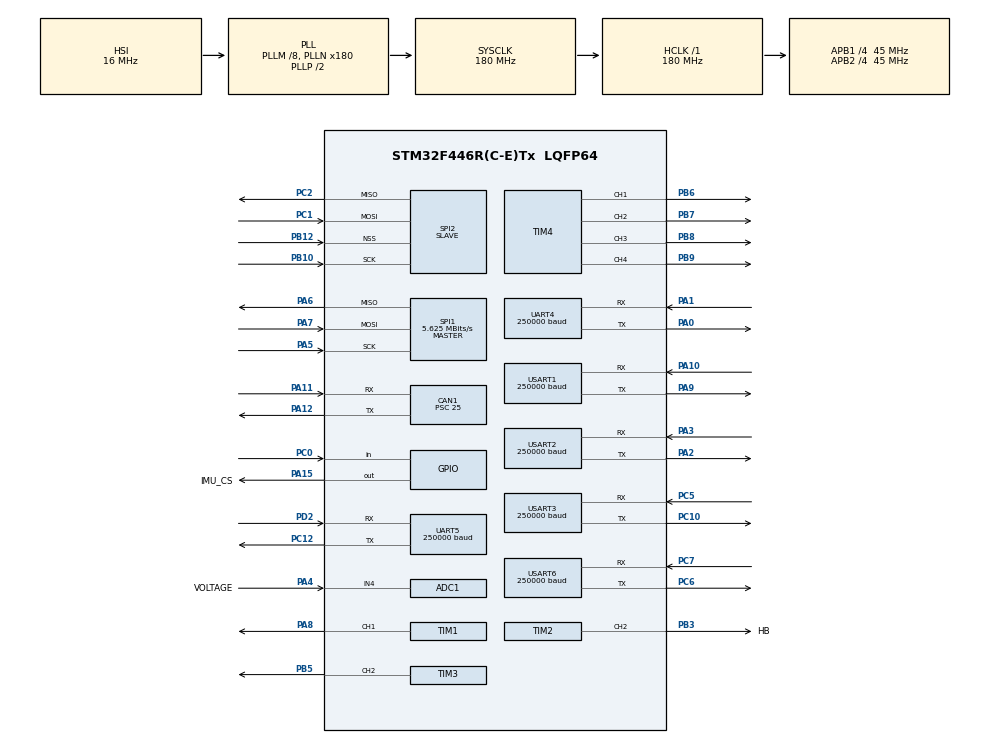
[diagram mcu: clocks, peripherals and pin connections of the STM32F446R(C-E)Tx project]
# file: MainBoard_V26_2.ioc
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ADC1.Channel-0\#ChannelRegularConversion=ADC_CHANNEL_4
ADC1.ContinuousConvMode=ENABLE
ADC1.DMAContinuousRequests=ENABLE
ADC1.NbrOfConversionFlag=1
ADC1.Rank-0\#ChannelRegularConversion=1
ADC1.SamplingTime-0\#ChannelRegularConversion=ADC_SAMPLETIME_56CYCLES
ADC1.ScanConvMode=ENABLE
ADC1.master=1
CAN1.BS1=CAN_BS1_15TQ
CAN1.BS2=CAN_BS2_2TQ
CAN1.CalculateBaudRate=100000
CAN1.CalculateTimeBit=10000
CAN1.CalculateTimeQuantum=555.5555555555555
CAN1.Prescaler=25
CAN1.TTCM=ENABLE
CAN1.TXFP=ENABLE
Dma.ADC1.10.Direction=DMA_PERIPH_TO_MEMORY
Dma.ADC1.10.FIFOMode=DMA_FIFOMODE_DISABLE
Dma.ADC1.10.Instance=DMA2_Stream0
Dma.ADC1.10.MemDataAlignment=DMA_MDATAALIGN_HALFWORD
Dma.ADC1.10.MemInc=DMA_MINC_ENABLE
Dma.ADC1.10.Mode=DMA_CIRCULAR
Dma.ADC1.10.PeriphDataAlignment=DMA_PDATAALIGN_HALFWORD
Dma.ADC1.10.PeriphInc=DMA_PINC_DISABLE
Dma.ADC1.10.Priority=DMA_PRIORITY_LOW
Dma.Request0=UART4_RX
Dma.Request1=SPI2_TX
Dma.Request10=ADC1
Dma.Request2=USART2_RX
Dma.Request3=USART2_TX
Dma.Request4=USART3_RX
Dma.Request5=SPI2_RX
Dma.Request6=UART5_RX
Dma.Request7=UART5_TX
Dma.Request8=USART6_RX
Dma.Request9=USART6_TX
Dma.SPI2_TX.1.Direction=DMA_MEMORY_TO_PERIPH
Dma.SPI2_TX.1.FIFOMode=DMA_FIFOMODE_DISABLE
Dma.SPI2_TX.1.Instance=DMA1_Stream4
Dma.SPI2_TX.1.MemDataAlignment=DMA_MDATAALIGN_BYTE
Dma.SPI2_TX.1.MemInc=DMA_MINC_ENABLE
Dma.SPI2_TX.1.Mode=DMA_NORMAL
Dma.SPI2_TX.1.PeriphDataAlignment=DMA_PDATAALIGN_BYTE
Dma.SPI2_TX.1.PeriphInc=DMA_PINC_DISABLE
Dma.SPI2_TX.1.Priority=DMA_PRIORITY_VERY_HIGH
Dma.SPI2_RX.5.Direction=DMA_PERIPH_TO_MEMORY
Dma.SPI2_RX.5.FIFOMode=DMA_FIFOMODE_DISABLE
Dma.SPI2_RX.5.Instance=DMA1_Stream3
Dma.SPI2_RX.5.MemDataAlignment=DMA_MDATAALIGN_BYTE
Dma.SPI2_RX.5.MemInc=DMA_MINC_ENABLE
Dma.SPI2_RX.5.Mode=DMA_NORMAL
Dma.SPI2_RX.5.PeriphDataAlignment=DMA_PDATAALIGN_BYTE
Dma.SPI2_RX.5.PeriphInc=DMA_PINC_DISABLE
Dma.SPI2_RX.5.Priority=DMA_PRIORITY_VERY_HIGH
Dma.UART4_RX.0.Direction=DMA_PERIPH_TO_MEMORY
Dma.UART4_RX.0.FIFOMode=DMA_FIFOMODE_DISABLE
Dma.UART4_RX.0.Instance=DMA1_Stream2
Dma.UART4_RX.0.MemDataAlignment=DMA_MDATAALIGN_BYTE
Dma.UART4_RX.0.MemInc=DMA_MINC_ENABLE
Dma.UART4_RX.0.Mode=DMA_CIRCULAR
Dma.UART4_RX.0.PeriphDataAlignment=DMA_PDATAALIGN_BYTE
Dma.UART4_RX.0.PeriphInc=DMA_PINC_DISABLE
Dma.UART4_RX.0.Priority=DMA_PRIORITY_LOW
Dma.UART5_RX.6.Direction=DMA_PERIPH_TO_MEMORY
Dma.UART5_RX.6.FIFOMode=DMA_FIFOMODE_DISABLE
Dma.UART5_RX.6.Instance=DMA1_Stream0
Dma.UART5_RX.6.MemDataAlignment=DMA_MDATAALIGN_BYTE
Dma.UART5_RX.6.MemInc=DMA_MINC_ENABLE
Dma.UART5_RX.6.Mode=DMA_CIRCULAR
Dma.UART5_RX.6.PeriphDataAlignment=DMA_PDATAALIGN_BYTE
Dma.UART5_RX.6.PeriphInc=DMA_PINC_DISABLE
Dma.UART5_RX.6.Priority=DMA_PRIORITY_LOW
Dma.UART5_TX.7.Direction=DMA_MEMORY_TO_PERIPH
Dma.UART5_TX.7.FIFOMode=DMA_FIFOMODE_DISABLE
Dma.UART5_TX.7.Instance=DMA1_Stream7
Dma.UART5_TX.7.MemDataAlignment=DMA_MDATAALIGN_BYTE
Dma.UART5_TX.7.MemInc=DMA_MINC_ENABLE
Dma.UART5_TX.7.Mode=DMA_NORMAL
Dma.UART5_TX.7.PeriphDataAlignment=DMA_PDATAALIGN_BYTE
Dma.UART5_TX.7.PeriphInc=DMA_PINC_DISABLE
Dma.UART5_TX.7.Priority=DMA_PRIORITY_LOW
Dma.USART2_RX.2.Direction=DMA_PERIPH_TO_MEMORY
Dma.USART2_RX.2.FIFOMode=DMA_FIFOMODE_DISABLE
Dma.USART2_RX.2.Instance=DMA1_Stream5
Dma.USART2_RX.2.MemDataAlignment=DMA_MDATAALIGN_BYTE
Dma.USART2_RX.2.MemInc=DMA_MINC_ENABLE
Dma.USART2_RX.2.Mode=DMA_CIRCULAR
Dma.USART2_RX.2.PeriphDataAlignment=DMA_PDATAALIGN_BYTE
Dma.USART2_RX.2.PeriphInc=DMA_PINC_DISABLE
Dma.USART2_RX.2.Priority=DMA_PRIORITY_LOW
Dma.USART2_TX.3.Direction=DMA_MEMORY_TO_PERIPH
Dma.USART2_TX.3.FIFOMode=DMA_FIFOMODE_DISABLE
Dma.USART2_TX.3.Instance=DMA1_Stream6
Dma.USART2_TX.3.MemDataAlignment=DMA_MDATAALIGN_BYTE
Dma.USART2_TX.3.MemInc=DMA_MINC_ENABLE
Dma.USART2_TX.3.Mode=DMA_NORMAL
Dma.USART2_TX.3.PeriphDataAlignment=DMA_PDATAALIGN_BYTE
Dma.USART2_TX.3.PeriphInc=DMA_PINC_DISABLE
Dma.USART2_TX.3.Priority=DMA_PRIORITY_LOW
Dma.USART3_RX.4.Direction=DMA_PERIPH_TO_MEMORY
Dma.USART3_RX.4.FIFOMode=DMA_FIFOMODE_DISABLE
Dma.USART3_RX.4.Instance=DMA1_Stream1
Dma.USART3_RX.4.MemDataAlignment=DMA_MDATAALIGN_BYTE
Dma.USART3_RX.4.MemInc=DMA_MINC_ENABLE
Dma.USART3_RX.4.Mode=DMA_CIRCULAR
Dma.USART3_RX.4.PeriphDataAlignment=DMA_PDATAALIGN_BYTE
Dma.USART3_RX.4.PeriphInc=DMA_PINC_DISABLE
Dma.USART3_RX.4.Priority=DMA_PRIORITY_LOW
Dma.USART6_RX.8.Direction=DMA_PERIPH_TO_MEMORY
Dma.USART6_RX.8.FIFOMode=DMA_FIFOMODE_DISABLE
Dma.USART6_RX.8.Instance=DMA2_Stream1
Dma.USART6_RX.8.MemDataAlignment=DMA_MDATAALIGN_BYTE
Dma.USART6_RX.8.MemInc=DMA_MINC_ENABLE
Dma.USART6_RX.8.Mode=DMA_CIRCULAR
Dma.USART6_RX.8.PeriphDataAlignment=DMA_PDATAALIGN_BYTE
Dma.USART6_RX.8.PeriphInc=DMA_PINC_DISABLE
Dma.USART6_RX.8.Priority=DMA_PRIORITY_LOW
Dma.USART6_TX.9.Direction=DMA_MEMORY_TO_PERIPH
Dma.USART6_TX.9.FIFOMode=DMA_FIFOMODE_DISABLE
Dma.USART6_TX.9.Instance=DMA2_Stream6
Dma.USART6_TX.9.MemDataAlignment=DMA_MDATAALIGN_BYTE
Dma.USART6_TX.9.MemInc=DMA_MINC_ENABLE
Dma.USART6_TX.9.Mode=DMA_NORMAL
Dma.USART6_TX.9.PeriphDataAlignment=DMA_PDATAALIGN_BYTE
Dma.USART6_TX.9.PeriphInc=DMA_PINC_DISABLE
Dma.USART6_TX.9.Priority=DMA_PRIORITY_LOW
Mcu.Family=STM32F4
Mcu.Name=STM32F446R(C-E)Tx
Mcu.Package=LQFP64
NVIC.CAN1_RX0_IRQn=true\:0\:0\:false\:false\:true\:true\:true\:true
NVIC.CAN1_RX1_IRQn=true\:0\:0\:false\:false\:true\:true\:true\:true
NVIC.CAN1_TX_IRQn=true\:0\:0\:false\:false\:true\:true\:true\:true
NVIC.DMA1_Stream0_IRQn=true\:0\:0\:false\:false\:true\:false\:true\:true
NVIC.DMA1_Stream1_IRQn=true\:0\:0\:false\:false\:true\:false\:true\:true
NVIC.DMA1_Stream2_IRQn=true\:0\:0\:false\:false\:true\:false\:true\:true
NVIC.DMA1_Stream3_IRQn=true\:0\:0\:false\:false\:true\:false\:true\:true
NVIC.DMA1_Stream4_IRQn=true\:0\:0\:false\:false\:true\:false\:true\:true
NVIC.DMA1_Stream5_IRQn=true\:0\:0\:false\:false\:true\:false\:true\:true
NVIC.DMA1_Stream6_IRQn=true\:0\:0\:false\:false\:true\:false\:true\:true
NVIC.DMA1_Stream7_IRQn=true\:0\:0\:false\:false\:true\:false\:true\:true
NVIC.DMA2_Stream0_IRQn=true\:0\:0\:false\:false\:true\:false\:true\:true
NVIC.DMA2_Stream1_IRQn=true\:0\:0\:false\:false\:true\:false\:true\:true
NVIC.DMA2_Stream6_IRQn=true\:0\:0\:false\:false\:true\:false\:true\:true
NVIC.PriorityGroup=NVIC_PRIORITYGROUP_4
NVIC.SPI1_IRQn=true\:0\:0\:false\:false\:true\:true\:true\:true
NVIC.SPI2_IRQn=true\:0\:0\:false\:false\:true\:true\:true\:true
NVIC.UART4_IRQn=true\:0\:0\:false\:false\:true\:true\:true\:true
NVIC.USART2_IRQn=true\:0\:0\:false\:false\:true\:true\:true\:true
PA0-WKUP.Mode=Asynchronous
PA0-WKUP.Signal=UART4_TX
PA1.Mode=Asynchronous
PA1.Signal=UART4_RX
PA10.Mode=Asynchronous
PA10.Signal=USART1_RX
PA11.Mode=CAN_Activate
PA11.Signal=CAN1_RX
PA12.Mode=CAN_Activate
PA12.Signal=CAN1_TX
PA13.Mode=Serial_Wire
PA13.Signal=SYS_JTMS-SWDIO
PA14.Mode=Serial_Wire
PA14.Signal=SYS_JTCK-SWCLK
PA15.GPIO_Label=IMU_CS
PA15.GPIO_PuPd=GPIO_NOPULL
PA15.PinState=GPIO_PIN_SET
PA15.Signal=GPIO_Output
PA2.Mode=Asynchronous
PA2.Signal=USART2_TX
PA3.Mode=Asynchronous
PA3.Signal=USART2_RX
PA4.GPIO_Label=VOLTAGE
PA4.Signal=ADCx_IN4
PA5.Mode=Full_Duplex_Slave
PA5.Signal=SPI1_SCK
PA6.Mode=Full_Duplex_Slave
PA6.Signal=SPI1_MISO
PA7.Mode=Full_Duplex_Slave
PA7.Signal=SPI1_MOSI
PA8.Signal=S_TIM1_CH1
PA9.Mode=Asynchronous
PA9.Signal=USART1_TX
PB10.Mode=Full_Duplex_Slave
PB10.Signal=SPI2_SCK
PB12.Mode=NSS_Signal_Hard_Input
PB12.Signal=SPI2_NSS
PB3.GPIO_Label=HB
PB3.Signal=S_TIM2_CH2
PB5.Signal=S_TIM3_CH2
PB6.Signal=S_TIM4_CH1
PB7.Signal=S_TIM4_CH2
PB8.Signal=S_TIM4_CH3
PB9.Signal=S_TIM4_CH4
PC0.Signal=GPIO_Input
PC1.Mode=Full_Duplex_Slave
PC1.Signal=SPI2_MOSI
PC10.Mode=Asynchronous
PC10.Signal=USART3_TX
PC12.Mode=Asynchronous
PC12.Signal=UART5_TX
PC2.Mode=Full_Duplex_Slave
PC2.Signal=SPI2_MISO
PC5.Mode=Asynchronous
PC5.Signal=USART3_RX
PC6.Mode=Asynchronous
PC6.Signal=USART6_TX
PC7.Mode=Asynchronous
PC7.Signal=USART6_RX
PD2.Mode=Asynchronous
PD2.Signal=UART5_RX
PH0-OSC_IN.Mode=HSE-External-Oscillator
PH0-OSC_IN.Signal=RCC_OSC_IN
PH1-OSC_OUT.Mode=HSE-External-Oscillator
PH1-OSC_OUT.Signal=RCC_OSC_OUT
ProjectManager.HeapSize=0x200
ProjectManager.StackSize=0x400
ProjectManager.TargetToolchain=Makefile
RCC.AHBFreq_Value=180000000
RCC.APB1CLKDivider=RCC_HCLK_DIV4
RCC.APB1Freq_Value=45000000
RCC.APB1TimFreq_Value=90000000
RCC.APB2CLKDivider=RCC_HCLK_DIV4
RCC.APB2Freq_Value=45000000
RCC.APB2TimFreq_Value=90000000
RCC.CortexFreq_Value=180000000
RCC.HCLKFreq_Value=180000000
RCC.HSE_VALUE=16000000
RCC.PLLM=8
RCC.PLLN=180
RCC.SYSCLKFreq_VALUE=180000000
RCC.SYSCLKSource=RCC_SYSCLKSOURCE_PLLCLK
RCC.USBFreq_Value=180000000
RCC.VCOOutputFreq_Value=360000000
SH.ADCx_IN4.0=ADC1_IN4,IN4
SH.S_TIM1_CH1.0=TIM1_CH1,PWM Generation1 CH1
SH.S_TIM2_CH2.0=TIM2_CH2,PWM Generation2 CH2
SH.S_TIM3_CH2.0=TIM3_CH2,PWM Generation2 CH2
SH.S_TIM4_CH1.0=TIM4_CH1,PWM Generation1 CH1
SH.S_TIM4_CH2.0=TIM4_CH2,PWM Generation2 CH2
SH.S_TIM4_CH3.0=TIM4_CH3,PWM Generation3 CH3
SH.S_TIM4_CH4.0=TIM4_CH4,PWM Generation4 CH4
SPI1.BaudRatePrescaler=SPI_BAUDRATEPRESCALER_8
SPI1.CalculateBaudRate=5.625 MBits/s
SPI1.Direction=SPI_DIRECTION_2LINES
SPI1.Mode=SPI_MODE_MASTER
SPI1.VirtualType=VM_MASTER
SPI2.CLKPolarity=SPI_POLARITY_LOW
SPI2.Direction=SPI_DIRECTION_2LINES
SPI2.Mode=SPI_MODE_SLAVE
SPI2.VirtualNSS=VM_NSSHARD
SPI2.VirtualType=VM_SLAVE
TIM1.Channel-PWM\ Generation1\ CH1=TIM_CHANNEL_1
TIM1.Period=8999
TIM1.Prescaler=9
TIM2.Channel-PWM\ Generation2\ CH2=TIM_CHANNEL_2
TIM2.Period=8999
TIM2.Prescaler=9
TIM3.Channel-PWM\ Generation2\ CH2=TIM_CHANNEL_2
TIM4.Channel-PWM\ Generation1\ CH1=TIM_CHANNEL_1
TIM4.Channel-PWM\ Generation2\ CH2=TIM_CHANNEL_2
TIM4.Channel-PWM\ Generation3\ CH3=TIM_CHANNEL_3
TIM4.Channel-PWM\ Generation4\ CH4=TIM_CHANNEL_4
UART4.BaudRate=250000
UART4.VirtualMode=Asynchronous
UART5.BaudRate=250000
UART5.VirtualMode=Asynchronous
USART1.BaudRate=250000
USART1.VirtualMode=VM_ASYNC
USART2.BaudRate=250000
USART2.VirtualMode=VM_ASYNC
USART3.BaudRate=250000
USART3.VirtualMode=VM_ASYNC
USART6.BaudRate=250000
USART6.VirtualMode=VM_ASYNC
board=custom

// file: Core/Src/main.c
/* USER CODE BEGIN Header */
/**
 ******************************************************************************
 * @file           : main.c
 * @brief          : Main program body
 ******************************************************************************
 * @attention
 *
 * Copyright (c) 2026 STMicroelectronics.
 * All rights reserved.
 *
 * This software is licensed under terms that can be found in the LICENSE file
 * in the root directory of this software component.
 * If no LICENSE file comes with this software, it is provided AS-IS.
 *
 ******************************************************************************
 */
/* USER CODE END Header */
#include "main.h"
#include "adc.h"
#include "can.h"
#include "dma.h"
#include "iwdg.h"
#include "spi.h"
#include "tim.h"
#include "usart.h"
#include "gpio.h"

/* USER CODE BEGIN Includes */
#include "app.h"
/* USER CODE END Includes */

void SystemClock_Config(void);

/* USER CODE BEGIN 0 */
int _write(int file, char* ptr, int len) {
  HAL_UART_Transmit(&huart1, (uint8_t*)ptr, len, 10);
  return len;
}
/* USER CODE END 0 */

int main(void)
{

  /* MCU Configuration--------------------------------------------------------*/

  /* Reset of all peripherals, Initializes the Flash interface and the Systick. */
  HAL_Init();

  /* Configure the system clock */
  SystemClock_Config();

  /* Initialize all configured peripherals */
  MX_GPIO_Init();
  MX_DMA_Init();
  MX_CAN1_Init();
  MX_SPI1_Init();
  MX_SPI2_Init();
  MX_UART4_Init();
  MX_UART5_Init();
  MX_USART1_UART_Init();
  MX_USART2_UART_Init();
  MX_USART3_UART_Init();
  MX_USART6_UART_Init();
  MX_ADC1_Init();
  MX_TIM1_Init();
  MX_TIM2_Init();
  MX_TIM3_Init();
  MX_TIM4_Init();
  MX_IWDG_Init();

  /* Infinite loop */
  /* USER CODE BEGIN WHILE */
  Setup();
  MainApp();
  while (1) {
    /* USER CODE END WHILE */

  }
}

void SystemClock_Config(void)
{
  RCC_OscInitTypeDef RCC_OscInitStruct = {0};
  RCC_ClkInitTypeDef RCC_ClkInitStruct = {0};

  /** Configure the main internal regulator output voltage
  */
  __HAL_RCC_PWR_CLK_ENABLE();
  __HAL_PWR_VOLTAGESCALING_CONFIG(PWR_REGULATOR_VOLTAGE_SCALE1);

  /** Initializes the RCC Oscillators according to the specified parameters
  * in the RCC_OscInitTypeDef structure.
  */
  RCC_OscInitStruct.OscillatorType = RCC_OSCILLATORTYPE_HSI;
  RCC_OscInitStruct.HSIState = RCC_HSI_ON;
  RCC_OscInitStruct.HSICalibrationValue = RCC_HSICALIBRATION_DEFAULT;
  RCC_OscInitStruct.PLL.PLLState = RCC_PLL_ON;
  RCC_OscInitStruct.PLL.PLLSource = RCC_PLLSOURCE_HSI;
  RCC_OscInitStruct.PLL.PLLM = 8;
  RCC_OscInitStruct.PLL.PLLN = 180;
  RCC_OscInitStruct.PLL.PLLP = RCC_PLLP_DIV2;
  RCC_OscInitStruct.PLL.PLLQ = 2;
  RCC_OscInitStruct.PLL.PLLR = 2;
  if (HAL_RCC_OscConfig(&RCC_OscInitStruct) != HAL_OK)
  {
    Error_Handler();
  }

  /** Activate the Over-Drive mode
  */
  if (HAL_PWREx_EnableOverDrive() != HAL_OK)
  {
    Error_Handler();
  }

  /** Initializes the CPU, AHB and APB buses clocks
  */
  RCC_ClkInitStruct.ClockType = RCC_CLOCKTYPE_HCLK|RCC_CLOCKTYPE_SYSCLK
                              |RCC_CLOCKTYPE_PCLK1|RCC_CLOCKTYPE_PCLK2;
  RCC_ClkInitStruct.SYSCLKSource = RCC_SYSCLKSOURCE_PLLCLK;
  RCC_ClkInitStruct.AHBCLKDivider = RCC_SYSCLK_DIV1;
  RCC_ClkInitStruct.APB1CLKDivider = RCC_HCLK_DIV4;
  RCC_ClkInitStruct.APB2CLKDivider = RCC_HCLK_DIV4;

  if (HAL_RCC_ClockConfig(&RCC_ClkInitStruct, FLASH_LATENCY_5) != HAL_OK)
  {
    Error_Handler();
  }
}

void Error_Handler(void)
{
  /* USER CODE BEGIN Error_Handler_Debug */
  __disable_irq();
  while (1) {
    HAL_GPIO_TogglePin(LED0_GPIO_Port, LED0_Pin);
    for (volatile int i = 0; i < 1000000; i++);
  }
  /* USER CODE END Error_Handler_Debug */
}
